VERSION ""

NS_ :

BS_:

BU_: UUT CTRL

BO_ 3221225472 VECTOR__INDEPENDENT_SIG_MSG: 0 Vector__XXX
 SG_ NewSignal_0012 : 0|8@1+ (1,0) [0|0] "" Vector__XXX
 SG_ NewSignal_0013 : 0|8@1+ (1,0) [0|0] "" Vector__XXX
 SG_ NewSignal_0001 : 0|2@1+ (1,0) [0|0] "" Vector__XXX
 SG_ TX_DIGIN m88 : 8|8@1+ (1,0) [0|0] "" Vector__XXX
 SG_ TX_AD2 m88 : 16|8@1+ (1,0) [0|0] "" Vector__XXX
 SG_ TX_AD3 m88 : 24|8@1+ (1,0) [0|0] "" Vector__XXX
 SG_ Ctrl_Sensor_Pwr_1 m81 : 40|2@1+ (1,0) [0|0] "" Vector__XXX
 SG_ Ctrl_Sensor_Pwr_2 m81 : 42|2@1+ (1,0) [0|0] "" Vector__XXX
 SG_ Ctrl_Sensor_Pwr_3 m81 : 44|2@1+ (1,0) [0|0] "" Vector__XXX
 SG_ Ctrl_Sensor_Pwr_4 m81 : 46|2@1+ (1,0) [0|0] "" Vector__XXX
 SG_ PWM_SIGN_PORT8 : 62|2@1+ (1,0) [0|0] "" Vector__XXX
 SG_ PWM_SIGN_PORT7 : 46|2@1+ (1,0) [0|0] "" Vector__XXX
 SG_ PWM_SIGN_PORT6 : 30|2@1+ (1,0) [0|0] "" Vector__XXX
 SG_ PWM_SIGN_PORT5 : 14|2@1+ (1,0) [0|0] "" Vector__XXX
 SG_ PWM_SIGN_PORT4 : 62|2@1+ (1,0) [0|0] "" Vector__XXX
 SG_ PWM_SIGN_PORT3 : 46|2@1+ (1,0) [0|0] "" Vector__XXX
 SG_ PWM_SIGN_PORT2 : 30|2@1+ (1,0) [0|0] "" Vector__XXX
 SG_ PWM_SIGN_PORT1 : 14|2@1+ (1,0) [0|0] "" Vector__XXX
 SG_ OUTPUT1A_Amps : 0|16@1+ (1,0) [0|0] "" Vector__XXX
 SG_ OUTPUT1B_Amps : 16|16@1+ (1,0) [0|0] "" Vector__XXX
 SG_ OUTPUT3A_Amps : 32|16@1+ (1,0) [0|0] "" Vector__XXX
 SG_ OUTPUT3B_Amps : 48|16@1+ (1,0) [0|0] "" Vector__XXX
 SG_ Port8_Kp m85 : 56|8@1+ (1,0) [0|0] "" Vector__XXX
 SG_ Port8_Ki m86 : 8|8@1+ (1,0) [0|0] "" Vector__XXX

BO_ 2565857489 CTRL1: 8 CTRL
 SG_ Command M : 0|8@1+ (1,0) [0|0] "" Vector__XXX
 SG_ Output1A m81 : 8|2@1+ (1,0) [0|0] "" Vector__XXX
 SG_ Output1B m81 : 10|2@1+ (1,0) [0|0] "" Vector__XXX
 SG_ Output2A m81 : 12|2@1+ (1,0) [0|0] "" Vector__XXX
 SG_ Output2B m81 : 14|2@1+ (1,0) [0|0] "" Vector__XXX
 SG_ Output3A m81 : 16|2@1+ (1,0) [0|0] "" Vector__XXX
 SG_ Output3B m81 : 18|2@1+ (1,0) [0|0] "" Vector__XXX
 SG_ Output4A m81 : 20|2@1+ (1,0) [0|0] "" Vector__XXX
 SG_ Output4B m81 : 22|2@1+ (1,0) [0|0] "" Vector__XXX
 SG_ Output5A m81 : 24|2@1+ (1,0) [0|0] "" Vector__XXX
 SG_ Output5B m81 : 26|2@1+ (1,0) [0|0] "" Vector__XXX
 SG_ Output6A m81 : 28|2@1+ (1,0) [0|0] "" Vector__XXX
 SG_ Output6B m81 : 30|2@1+ (1,0) [0|0] "" Vector__XXX
 SG_ Output7A m81 : 32|2@1+ (1,0) [0|0] "" Vector__XXX
 SG_ Output7B m81 : 34|2@1+ (1,0) [0|0] "" Vector__XXX
 SG_ Output8A m81 : 36|2@1+ (1,0) [0|0] "" Vector__XXX
 SG_ Output8B m81 : 38|2@1+ (1,0) [0|0] "" Vector__XXX
 SG_ Enable_Fault_Reset m82 : 8|2@1+ (1,0) [0|0] "" Vector__XXX
 SG_ Enable_DPLF1 m82 : 10|2@1+ (1,0) [0|0] "" Vector__XXX
 SG_ Enable_DPLF2 m82 : 12|2@1+ (1,0) [0|0] "" Vector__XXX
 SG_ Enable_DPLTx m82 : 14|2@1+ (1,0) [0|0] "" Vector__XXX
 SG_ SaveSettings m82 : 18|2@1+ (1,0) [0|0] "" Vector__XXX
 SG_ ADRaw m82 : 20|2@1+ (1,0) [0|0] "" Vector__XXX
 SG_ FREQ1 m82 : 32|16@1+ (1,0) [0|0] "" Vector__XXX
 SG_ MODE1 m82 : 48|4@1+ (1,0) [0|0] "" Vector__XXX
 SG_ MODE2 m82 : 52|4@1+ (1,0) [0|0] "" Vector__XXX
 SG_ ID1 m82 : 56|8@1+ (1,0) [0|0] "" Vector__XXX
 SG_ MODE1A m83 : 8|4@1+ (1,0) [0|0] "" Vector__XXX
 SG_ MODE1B m83 : 12|4@1+ (1,0) [0|0] "" Vector__XXX
 SG_ MODE2A m83 : 16|4@1+ (1,0) [0|0] "" Vector__XXX
 SG_ MODE2B m83 : 20|4@1+ (1,0) [0|0] "" Vector__XXX
 SG_ MODE3A m83 : 24|4@1+ (1,0) [0|0] "" Vector__XXX
 SG_ MODE3B m83 : 28|4@1+ (1,0) [0|0] "" Vector__XXX
 SG_ MODE4A m83 : 32|4@1+ (1,0) [0|0] "" Vector__XXX
 SG_ MODE4B m83 : 36|4@1+ (1,0) [0|0] "" Vector__XXX
 SG_ MODE5A m83 : 40|4@1+ (1,0) [0|0] "" Vector__XXX
 SG_ MODE5B m83 : 44|4@1+ (1,0) [0|0] "" Vector__XXX
 SG_ MODE6A m83 : 48|4@1+ (1,0) [0|0] "" Vector__XXX
 SG_ MODE6B m83 : 52|4@1+ (1,0) [0|0] "" Vector__XXX
 SG_ MODE7A m83 : 56|4@1+ (1,0) [0|0] "" Vector__XXX
 SG_ MODE7B m83 : 60|4@1+ (1,0) [0|0] "" Vector__XXX
 SG_ MODE8A m84 : 8|4@1+ (1,0) [0|0] "" Vector__XXX
 SG_ MODE8B m84 : 12|4@1+ (1,0) [0|0] "" Vector__XXX
 SG_ Port1A_Kp m84 : 16|8@1+ (1,0) [0|0] "" Vector__XXX
 SG_ Port1A_Ki m84 : 24|8@1+ (1,0) [0|0] "" Vector__XXX
 SG_ Port1B_Kp m84 : 32|8@1+ (1,0) [0|0] "" Vector__XXX
 SG_ Port1B_Ki m84 : 40|8@1+ (1,0) [0|0] "" Vector__XXX
 SG_ Port2A_Kp m84 : 48|8@1+ (1,0) [0|0] "" Vector__XXX
 SG_ Port2A_Ki m84 : 56|8@1+ (1,0) [0|0] "" Vector__XXX
 SG_ Port2B_Kp m85 : 8|8@1+ (1,0) [0|0] "" Vector__XXX
 SG_ Port2B_Ki m85 : 16|8@1+ (1,0) [0|0] "" Vector__XXX
 SG_ Port3A_Kp m85 : 24|8@1+ (1,0) [0|0] "" Vector__XXX
 SG_ Port3A_Ki m85 : 32|8@1+ (1,0) [0|0] "" Vector__XXX
 SG_ Port3B_Kp m85 : 40|8@1+ (1,0) [0|0] "" Vector__XXX
 SG_ Port3B_Ki m85 : 48|8@1+ (1,0) [0|0] "" Vector__XXX
 SG_ Port4A_Kp m86 : 8|8@1+ (1,0) [0|0] "" Vector__XXX
 SG_ Port4A_Ki m86 : 16|8@1+ (1,0) [0|0] "" Vector__XXX
 SG_ Port4B_Kp m86 : 24|8@1+ (1,0) [0|0] "" Vector__XXX
 SG_ Port4B_Ki m86 : 32|8@1+ (1,0) [0|0] "" Vector__XXX
 SG_ Port5A_Kp m86 : 40|8@1+ (1,0) [0|0] "" Vector__XXX
 SG_ Port5A_Ki m86 : 48|8@1+ (1,0) [0|0] "" Vector__XXX
 SG_ Port5B_Kp m86 : 56|8@1+ (1,0) [0|0] "" Vector__XXX
 SG_ OUTPUT1A_Limit m88 : 8|8@1+ (1,0) [0|0] "" Vector__XXX
 SG_ OUTPUT3A_Limit m88 : 40|8@1+ (1,0) [0|0] "" Vector__XXX
 SG_ Port5B_Ki m89 : 8|8@1+ (1,0) [0|0] "" Vector__XXX
 SG_ Port6A_Kp m89 : 16|8@1+ (1,0) [0|0] "" Vector__XXX
 SG_ Port6A_Ki m89 : 24|8@1+ (1,0) [0|0] "" Vector__XXX
 SG_ Port6B_Kp m89 : 32|8@1+ (1,0) [0|0] "" Vector__XXX
 SG_ Port6B_Ki m89 : 40|8@1+ (1,0) [0|0] "" Vector__XXX
 SG_ Port7A_Kp m89 : 48|8@1+ (1,0) [0|0] "" Vector__XXX
 SG_ Port7A_Ki m89 : 56|8@1+ (1,0) [0|0] "" Vector__XXX
 SG_ Port7B_Kp m90 : 8|8@1+ (1,0) [0|0] "" Vector__XXX
 SG_ Port7B_Ki m90 : 16|8@1+ (1,0) [0|0] "" Vector__XXX
 SG_ Port8A_Kp m90 : 24|8@1+ (1,0) [0|0] "" Vector__XXX
 SG_ Port8A_Ki m90 : 32|8@1+ (1,0) [0|0] "" Vector__XXX
 SG_ Port8B_Kp m90 : 40|8@1+ (1,0) [0|0] "" Vector__XXX
 SG_ Port8B_Ki m90 : 48|8@1+ (1,0) [0|0] "" Vector__XXX
 SG_ PORT1_MODE m93 : 8|4@1+ (1,0) [0|0] "" Vector__XXX
 SG_ PORT2_MODE m93 : 12|4@1+ (1,0) [0|0] "" Vector__XXX
 SG_ PORT3_MODE m93 : 16|4@1+ (1,0) [0|0] "" Vector__XXX
 SG_ PORT4_MODE m93 : 20|4@1+ (1,0) [0|0] "" Vector__XXX
 SG_ PORT5_MODE m93 : 24|4@1+ (1,0) [0|0] "" Vector__XXX
 SG_ PORT6_MODE m93 : 28|4@1+ (1,0) [0|0] "" Vector__XXX
 SG_ PORT7_MODE m93 : 32|4@1+ (1,0) [0|0] "" Vector__XXX
 SG_ PORT8_MODE m93 : 36|4@1+ (1,0) [0|0] "" Vector__XXX

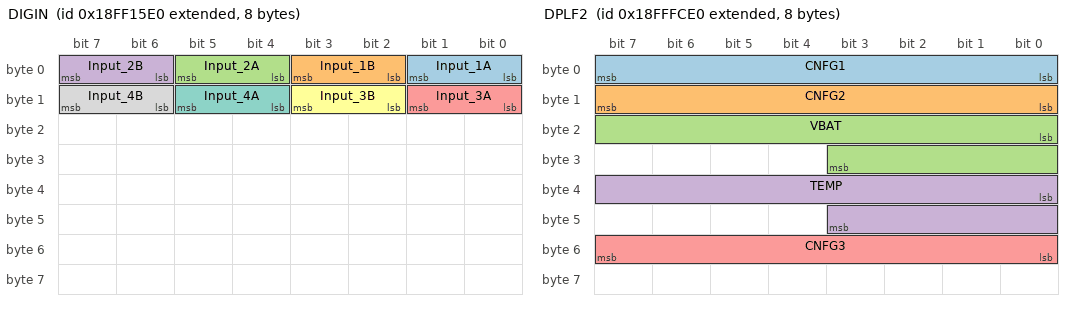
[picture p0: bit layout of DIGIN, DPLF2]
BO_ 2566854112 DIGIN: 8 UUT
 SG_ Input_1A : 0|2@1+ (1,0) [0|0] "BitPair" Vector__XXX
 SG_ Input_1B : 2|2@1+ (1,0) [0|0] "BitPair" Vector__XXX
 SG_ Input_2A : 4|2@1+ (1,0) [0|0] "BitPair" Vector__XXX
 SG_ Input_2B : 6|2@1+ (1,0) [0|0] "BitPair" Vector__XXX
 SG_ Input_3A : 8|2@1+ (1,0) [0|0] "BitPair" Vector__XXX
 SG_ Input_3B : 10|2@1+ (1,0) [0|0] "BitPair" Vector__XXX
 SG_ Input_4A : 12|2@1+ (1,0) [0|0] "BitPair" Vector__XXX
 SG_ Input_4B : 14|2@1+ (1,0) [0|0] "BitPair" Vector__XXX

BO_ 2566854368 AD2: 8 UUT
 SG_ Port_1A : 0|16@1+ (0.001,0) [0|0] "" Vector__XXX
 SG_ Port_1B : 16|16@1+ (0.001,0) [0|0] "" Vector__XXX
 SG_ Port_2A : 32|16@1+ (0.001,0) [0|0] "" Vector__XXX
 SG_ Port_2B : 48|16@1+ (0.001,0) [0|0] "" Vector__XXX
 SG_ Feedback_1A : 0|16@1+ (0.1,0) [0|0] "" Vector__XXX
 SG_ Feedback_1B : 16|16@1+ (0.1,0) [0|0] "" Vector__XXX
 SG_ Feedback_2A : 32|16@1+ (0.1,0) [0|0] "" Vector__XXX
 SG_ Feedback_2B : 48|16@1+ (0.1,0) [0|0] "" Vector__XXX

BO_ 2566854624 AD3: 8 UUT
 SG_ Port_3A : 0|16@1+ (0.001,0) [0|0] "" Vector__XXX
 SG_ Port_3B : 16|16@1+ (0.001,0) [0|0] "" Vector__XXX
 SG_ Port_4A : 32|16@1+ (0.001,0) [0|0] "" Vector__XXX
 SG_ Port_4B : 48|16@1+ (0.001,0) [0|0] "" Vector__XXX
 SG_ Feedback_3A : 0|16@1+ (0.1,0) [0|0] "" Vector__XXX
 SG_ Feedback_3B : 16|16@1+ (0.1,0) [0|0] "" Vector__XXX
 SG_ Feedback_4A : 32|16@1+ (0.1,0) [0|0] "" Vector__XXX
 SG_ Feedback_4B : 48|16@1+ (0.1,0) [0|0] "" Vector__XXX

BO_ 2565853664 STAT: 8 UUT
 SG_ Version : 0|8@1+ (1,0) [0|255] "Dec" Vector__XXX
 SG_ Revision : 8|8@1+ (1,0) [0|255] "Dec" Vector__XXX
 SG_ Factory_Default_Configuration : 16|2@1+ (1,0) [0|0] "Bit" Vector__XXX
 SG_ Configuration_Saved : 18|2@1+ (1,0) [0|0] "Bit" Vector__XXX
 SG_ Alternate_Configuration_Saved : 20|2@1+ (1,0) [0|0] "Bit" Vector__XXX
 SG_ Node_Alive : 22|2@1+ (1,0) [0|0] "Bit" Vector__XXX
 SG_ Node_Fault_Present : 24|2@1+ (1,0) [0|0] "Bit" Vector__XXX
 SG_ Fault_Counter_Not_Zero : 26|2@1+ (1,0) [0|0] "Bit" Vector__XXX
 SG_ Spare : 28|2@1+ (1,0) [0|0] "Bit" Vector__XXX
 SG_ Invalid_Configuration_Received : 30|2@1+ (1,0) [0|0] "Bit" Vector__XXX
 SG_ Active_Fault_Code : 32|8@1+ (1,0) [0|0] "Dec" Vector__XXX
 SG_ UserID : 40|8@1+ (1,0) [0|0] "Dec" Vector__XXX
 SG_ D25 : 48|2@1+ (1,0) [0|0] "Bit" Vector__XXX
 SG_ D26 : 50|2@1+ (1,0) [0|0] "Bit" Vector__XXX
 SG_ D27 : 52|2@1+ (1,0) [0|0] "Bit" Vector__XXX
 SG_ D28 : 54|2@1+ (1,0) [0|0] "Bit" Vector__XXX
 SG_ D29 : 56|2@1+ (1,0) [0|0] "Bit" Vector__XXX
 SG_ D30 : 58|2@1+ (1,0) [0|0] "Bit" Vector__XXX
 SG_ Hardware_Dash : 60|4@1+ (1,0) [0|0] "Dec" Vector__XXX

BO_ 2566912992 DPLF1: 8 UUT
 SG_ Input_1_BAUD1 : 0|2@1+ (1,0) [0|0] "Bit" Vector__XXX
 SG_ Input_2_CNFG1 : 2|2@1+ (1,0) [0|0] "Bit" Vector__XXX
 SG_ Input_3_CNFG2 : 4|2@1+ (1,0) [0|0] "Bit" Vector__XXX
 SG_ Input_4_CNFG3 : 6|2@1+ (1,0) [0|0] "Bit" Vector__XXX
 SG_ Input_5_CNFG4 : 8|2@1+ (1,0) [0|0] "Bit" Vector__XXX
 SG_ OutStat1A : 16|2@1+ (1,0) [0|0] "Bit" Vector__XXX
 SG_ OutStat1B : 18|2@1+ (1,0) [0|0] "Bit" Vector__XXX
 SG_ OutStat2A : 20|2@1+ (1,0) [0|0] "Bit" Vector__XXX
 SG_ OutStat2B : 22|2@1+ (1,0) [0|0] "Bit" Vector__XXX
 SG_ OutStat3A : 24|2@1+ (1,0) [0|0] "Bit" Vector__XXX
 SG_ OutStat3B : 26|2@1+ (1,0) [0|0] "Bit" Vector__XXX
 SG_ OutStat4A : 28|2@1+ (1,0) [0|0] "Bit" Vector__XXX
 SG_ OutStat4B : 30|2@1+ (1,0) [0|0] "Bit" Vector__XXX
 SG_ OutStat5A : 32|2@1+ (1,0) [0|0] "Bit" Vector__XXX
 SG_ OutStat5B : 34|2@1+ (1,0) [0|0] "Bit" Vector__XXX
 SG_ OutStat6A : 36|2@1+ (1,0) [0|0] "Bit" Vector__XXX
 SG_ OutStat6B : 38|2@1+ (1,0) [0|0] "Bit" Vector__XXX
 SG_ OutStat7A : 40|2@1+ (1,0) [0|0] "Bit" Vector__XXX
 SG_ OutStat7B : 42|2@1+ (1,0) [0|0] "Bit" Vector__XXX
 SG_ OutStat8A : 44|2@1+ (1,0) [0|0] "Bit" Vector__XXX
 SG_ OutStat8B : 46|2@1+ (1,0) [0|0] "Bit" Vector__XXX
 SG_ PowerBusP1 : 48|2@1+ (1,0) [0|0] "Bit" Vector__XXX
 SG_ PowerBusP2 : 50|2@1+ (1,0) [0|0] "Bit" Vector__XXX
 SG_ PowerBusP3 : 52|2@1+ (1,0) [0|0] "Bit" Vector__XXX
 SG_ PowerBusP4 : 54|2@1+ (1,0) [0|0] "Bit" Vector__XXX
 SG_ Save_Counter : 56|8@1+ (1,0) [0|0] "Int" Vector__XXX

BO_ 2566913248 DPLF2: 8 UUT
 SG_ CNFG1 : 0|8@1+ (1,0) [1|50] "Int" Vector__XXX
 SG_ CNFG2 : 8|8@1+ (1,0) [1|36] "Int" Vector__XXX
 SG_ VBAT : 16|12@1+ (0.1,0) [0|32] "Vdc" Vector__XXX
 SG_ TEMP : 32|12@1+ (0.1,-100) [-100|300] "F" Vector__XXX
 SG_ CNFG3 : 48|8@1+ (1,0) [1|250] "Int" Vector__XXX

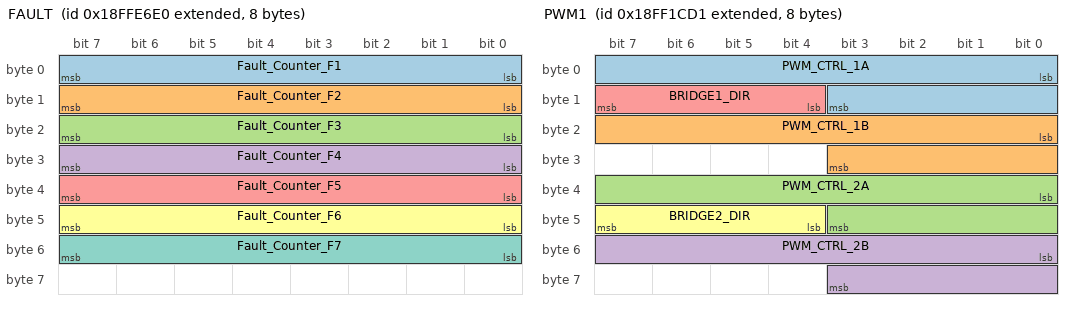
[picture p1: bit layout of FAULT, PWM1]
BO_ 2566907616 FAULT: 8 UUT
 SG_ Fault_Counter_F1 : 0|8@1+ (1,0) [0|250] "Dec" Vector__XXX
 SG_ Fault_Counter_F2 : 8|8@1+ (1,0) [0|250] "Dec" Vector__XXX
 SG_ Fault_Counter_F3 : 16|8@1+ (1,0) [0|250] "Dec" Vector__XXX
 SG_ Fault_Counter_F4 : 24|8@1+ (1,0) [0|250] "Dec" Vector__XXX
 SG_ Fault_Counter_F5 : 32|8@1+ (1,0) [0|250] "Dec" Vector__XXX
 SG_ Fault_Counter_F6 : 40|8@1+ (1,0) [0|250] "Dec" Vector__XXX
 SG_ Fault_Counter_F7 : 48|8@1+ (1,0) [0|250] "Dec" Vector__XXX

BO_ 2566855889 PWM1: 8 CTRL
 SG_ PWM_CTRL_1A : 0|12@1+ (1,0) [0|0] "" Vector__XXX
 SG_ PWM_CTRL_1B : 16|12@1+ (1,0) [0|0] "" Vector__XXX
 SG_ PWM_CTRL_2A : 32|12@1+ (1,0) [0|0] "" Vector__XXX
 SG_ PWM_CTRL_2B : 48|12@1+ (1,0) [0|0] "" Vector__XXX
 SG_ BRIDGE1_DIR : 12|4@1+ (1,0) [0|0] "" Vector__XXX
 SG_ BRIDGE2_DIR : 44|4@1+ (1,0) [0|0] "" Vector__XXX

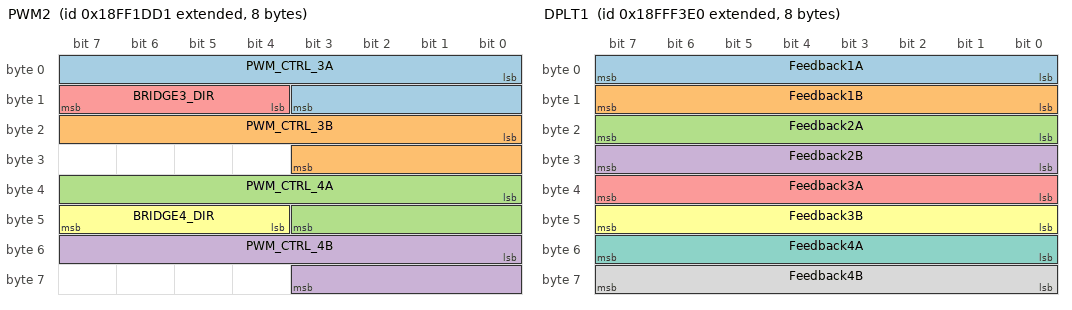
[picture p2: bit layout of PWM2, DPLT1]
BO_ 2566856145 PWM2: 8 CTRL
 SG_ PWM_CTRL_3A : 0|12@1+ (1,0) [0|0] "" Vector__XXX
 SG_ PWM_CTRL_3B : 16|12@1+ (1,0) [0|0] "" Vector__XXX
 SG_ PWM_CTRL_4A : 32|12@1+ (1,0) [0|0] "" Vector__XXX
 SG_ PWM_CTRL_4B : 48|12@1+ (1,0) [0|0] "" Vector__XXX
 SG_ BRIDGE3_DIR : 12|4@1+ (1,0) [0|0] "" Vector__XXX
 SG_ BRIDGE4_DIR : 44|4@1+ (1,0) [0|0] "" Vector__XXX

BO_ 2566910944 DPLT1: 8 UUT
 SG_ Feedback1A : 0|8@1+ (0.1,0) [0|0] "" Vector__XXX
 SG_ Feedback1B : 8|8@1+ (0.1,0) [0|0] "" Vector__XXX
 SG_ Feedback2A : 16|8@1+ (0.1,0) [0|0] "" Vector__XXX
 SG_ Feedback2B : 24|8@1+ (0.1,0) [0|0] "" Vector__XXX
 SG_ Feedback3A : 32|8@1+ (0.1,0) [0|0] "" Vector__XXX
 SG_ Feedback3B : 40|8@1+ (0.1,0) [0|0] "" Vector__XXX
 SG_ Feedback4A : 48|8@1+ (0.1,0) [0|0] "" Vector__XXX
 SG_ Feedback4B : 56|8@1+ (0.1,0) [0|0] "" Vector__XXX

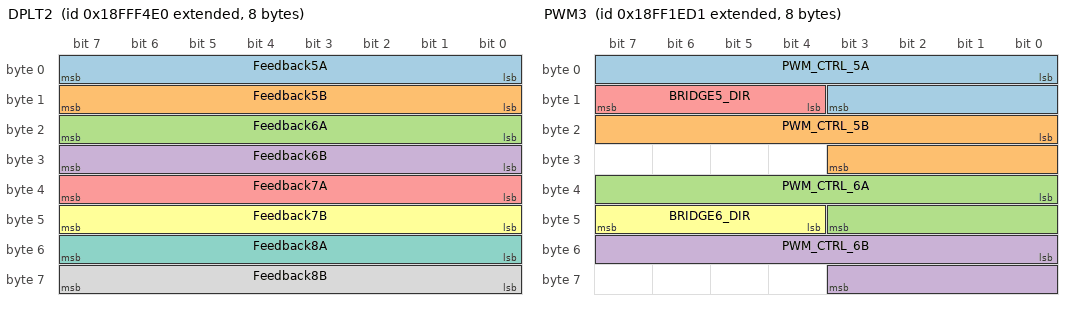
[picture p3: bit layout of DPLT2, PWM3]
BO_ 2566911200 DPLT2: 8 UUT
 SG_ Feedback5A : 0|8@1+ (0.1,0) [0|0] "" Vector__XXX
 SG_ Feedback5B : 8|8@1+ (0.1,0) [0|0] "" Vector__XXX
 SG_ Feedback6A : 16|8@1+ (0.1,0) [0|0] "" Vector__XXX
 SG_ Feedback6B : 24|8@1+ (0.1,0) [0|0] "" Vector__XXX
 SG_ Feedback7A : 32|8@1+ (0.1,0) [0|0] "" Vector__XXX
 SG_ Feedback7B : 40|8@1+ (0.1,0) [0|0] "" Vector__XXX
 SG_ Feedback8A : 48|8@1+ (0.1,0) [0|0] "" Vector__XXX
 SG_ Feedback8B : 56|8@1+ (0.1,0) [0|0] "" Vector__XXX

BO_ 2566856401 PWM3: 8 CTRL
 SG_ PWM_CTRL_5A : 0|12@1+ (1,0) [0|0] "" Vector__XXX
 SG_ PWM_CTRL_5B : 16|12@1+ (1,0) [0|0] "" Vector__XXX
 SG_ PWM_CTRL_6A : 32|12@1+ (1,0) [0|0] "" Vector__XXX
 SG_ PWM_CTRL_6B : 48|12@1+ (1,0) [0|0] "" Vector__XXX
 SG_ BRIDGE5_DIR : 12|4@1+ (1,0) [0|0] "" Vector__XXX
 SG_ BRIDGE6_DIR : 44|4@1+ (1,0) [0|0] "" Vector__XXX

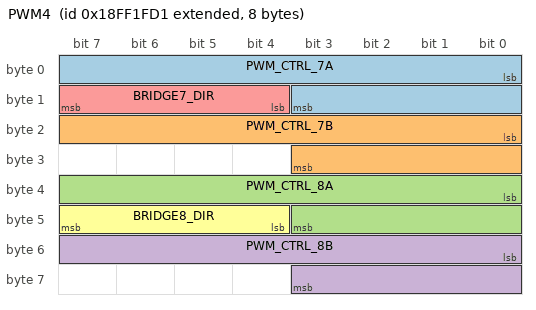
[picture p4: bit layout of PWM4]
BO_ 2566856657 PWM4: 8 CTRL
 SG_ PWM_CTRL_7A : 0|12@1+ (1,0) [0|0] "" Vector__XXX
 SG_ PWM_CTRL_7B : 16|12@1+ (1,0) [0|0] "" Vector__XXX
 SG_ PWM_CTRL_8A : 32|12@1+ (1,0) [0|0] "" Vector__XXX
 SG_ PWM_CTRL_8B : 48|12@1+ (1,0) [0|0] "" Vector__XXX
 SG_ BRIDGE7_DIR : 12|4@1+ (1,0) [0|0] "" Vector__XXX
 SG_ BRIDGE8_DIR : 44|4@1+ (1,0) [0|0] "" Vector__XXX

CM_ SG_ 3221225472 Ctrl_Sensor_Pwr_1 "Sensor power output control J1";
CM_ SG_ 3221225472 Ctrl_Sensor_Pwr_2 "Sensor power output control J2";
CM_ SG_ 3221225472 Ctrl_Sensor_Pwr_3 "Sensor power output control J3";
CM_ SG_ 3221225472 Ctrl_Sensor_Pwr_4 "Sensor power output control J4";
CM_ BO_ 2565857489 "Control Message #1";
CM_ SG_ 2565857489 Output1A "Bit Pair output ON/OFF control";
CM_ SG_ 2565857489 Output1B "Bit Pair output ON/OFF control";
CM_ SG_ 2565857489 Output2A "Bit Pair output ON/OFF control";
CM_ SG_ 2565857489 Output2B "Bit Pair output ON/OFF control";
CM_ SG_ 2565857489 Output3A "Bit Pair output ON/OFF control";
CM_ SG_ 2565857489 Output3B "Bit Pair output ON/OFF control";
CM_ SG_ 2565857489 Output4A "Bit Pair output ON/OFF control";
CM_ SG_ 2565857489 Output4B "Bit Pair output ON/OFF control";
CM_ SG_ 2565857489 Output5A "Bit Pair output ON/OFF control";
CM_ SG_ 2565857489 Output5B "Bit Pair output ON/OFF control";
CM_ SG_ 2565857489 Output6A "Bit Pair output ON/OFF control";
CM_ SG_ 2565857489 Output6B "Bit Pair output ON/OFF control";
CM_ SG_ 2565857489 Output7A "Bit Pair output ON/OFF control";
CM_ SG_ 2565857489 Output7B "Bit Pair output ON/OFF control";
CM_ SG_ 2565857489 Output8A "Bit Pair output ON/OFF control";
CM_ SG_ 2565857489 Output8B "Bit Pair output ON/OFF control";
CM_ SG_ 2565857489 Enable_Fault_Reset "Enables Controller Mode Output Reset.";
CM_ SG_ 2565857489 Enable_DPLF1 "Enables transmission of message [DPLF1]";
CM_ SG_ 2565857489 Enable_DPLF2 "Enables transmission of message [DPLF2]";
CM_ SG_ 2565857489 Enable_DPLTx "Not Used.  Reserved for enables transmission of message [DPLT1] and [DPLT2].";
CM_ SG_ 2565857489 SaveSettings "Set true to write configuration to module.  Preserves settings on power cycle.";
CM_ SG_ 2565857489 ADRaw "Enables analog inputs to be transmitted as raw bits without processing.";
CM_ SG_ 2565857489 FREQ1 "Not Used.  Reserved for PWM.";
CM_ SG_ 2565857489 MODE1 "Not Used.  Reserved for outputs.";
CM_ SG_ 2565857489 MODE2 "Global control sets the configuration for control of ALL inputs.";
CM_ SG_ 2565857489 ID1 "User defined byte for configuration ID.";
CM_ BO_ 2566854112 "Inputs Message";
CM_ SG_ 2566854112 Input_1A "Digital Input Status 1A";
CM_ SG_ 2566854112 Input_1B "Digital Input Status 1B";
CM_ SG_ 2566854112 Input_2A "Digital Input Status 2A";
CM_ SG_ 2566854112 Input_2B "Digital Input Status 2B";
CM_ SG_ 2566854112 Input_3A "Digital Input Status 3A";
CM_ SG_ 2566854112 Input_3B "Digital Input Status 3B";
CM_ SG_ 2566854112 Input_4A "Digital Input Status 4A";
CM_ SG_ 2566854112 Input_4B "Digital Input Status 4B";
CM_ BO_ 2566854368 "Analog Input Message 2";
CM_ SG_ 2566854368 Port_1A "Analog Input Port 1A";
CM_ SG_ 2566854368 Port_1B "Analog Input Port 1B";
CM_ SG_ 2566854368 Port_2A "Analog Input Port 2A";
CM_ SG_ 2566854368 Port_2B "Analog Input Port 2B";
CM_ BO_ 2566854624 "Analog Input Message 3";
CM_ SG_ 2566854624 Port_3A "Analog Input Port 3A";
CM_ SG_ 2566854624 Port_3B "Analog Input Port 3B";
CM_ SG_ 2566854624 Port_4A "Analog Input Port 4A";
CM_ SG_ 2566854624 Port_4B "Analog Input Port 4B";
CM_ BO_ 2565853664 "Proprietary A Default Response Message ";
CM_ SG_ 2565853664 Version "Software Version";
CM_ SG_ 2565853664 Revision "Software Revision";
CM_ SG_ 2565853664 Factory_Default_Configuration "Factory Default Configuration";
CM_ SG_ 2565853664 Configuration_Saved "Configuration Saved";
CM_ SG_ 2565853664 Alternate_Configuration_Saved "Alternate Configuration Received ";
CM_ SG_ 2565853664 Node_Alive "Node Alive:  Set to 0x01b";
CM_ SG_ 2565853664 Node_Fault_Present "Node Fault Present";
CM_ SG_ 2565853664 Fault_Counter_Not_Zero "Fault Counters Not Zero";
CM_ SG_ 2565853664 Spare "Spare - Set to 0x11b";
CM_ SG_ 2565853664 Invalid_Configuration_Received "Invalid Configuration Received";
CM_ SG_ 2565853664 Active_Fault_Code "Active Fault Code";
CM_ SG_ 2565853664 UserID "User ID";
CM_ SG_ 2565853664 D25 "True when message COMMAND 0x52h, times out after 1 second.";
CM_ SG_ 2565853664 D26 "True when message COMMAND 0x53h, times out after 1 second.";
CM_ SG_ 2565853664 D27 "True when message COMMAND 0x54h, times out after 1 second.";
CM_ SG_ 2565853664 D28 "True when message COMMAND 0x55h, times out after 1 second.";
CM_ SG_ 2565853664 D29 "True when message COMMAND 0x56h, times out after 1 second.";
CM_ SG_ 2565853664 D30 "True when message COMMAND 0x57h, times out after 1 second.";
CM_ SG_ 2565853664 Hardware_Dash "Hardware Identification";
CM_ BO_ 2566912992 "Status Message";
CM_ SG_ 2566912992 Save_Counter "Counter for SAVECNFG";
CM_ BO_ 2566913248 "Status Message";
CM_ SG_ 2566913248 CNFG1 "Hardware Configuration ";
CM_ SG_ 2566913248 CNFG2 "PC Board Revision ";
CM_ SG_ 2566913248 VBAT "Battery Voltage";
CM_ SG_ 2566913248 TEMP "Module Temp";
CM_ SG_ 2566913248 CNFG3 "Additional Configuration ";
CM_ BO_ 2566907616 "Node Fault Counter Message";
CM_ SG_ 2566907616 Fault_Counter_F1 "Fault Counter F1";
CM_ SG_ 2566907616 Fault_Counter_F2 "Fault Counter F2";
CM_ SG_ 2566907616 Fault_Counter_F3 "Fault Counter F3";
CM_ SG_ 2566907616 Fault_Counter_F4 "Fault Counter F4";
CM_ SG_ 2566907616 Fault_Counter_F5 "Fault Counter F5";
CM_ SG_ 2566907616 Fault_Counter_F6 "Fault Counter F6";
CM_ SG_ 2566907616 Fault_Counter_F7 "Fault Counter F7";
CM_ BO_ 2566855889 "Control Message #2";
CM_ BO_ 2566856145 "Control Message #3";
CM_ BO_ 2566910944 "Status Message";
CM_ BO_ 2566911200 "Status Message";
CM_ BO_ 2566856401 "Control Message #4";
CM_ BO_ 2566856657 "Control Message #5";
VAL_ 2565853664 Active_Fault_Code 7 "EEPROM" 8 "VREF" 9 "I2C" 10 "CNFG" 11 "PROG" 12 "CHECKSUM" 21 "VOLT_LOW" 22 "VOLT_HI" 31 "COM_SA" 32 "COM_HW" 33 "COM_CTRL" 41 "VOLT_HOLD" 51 "OUTPUT_OVERCURRENT" 52 "OUTPUT_SHORT" 53 "INPUT_OVERVOLTAGE" 54 "OVER_TEMP" 0 "CLEAR" ;
